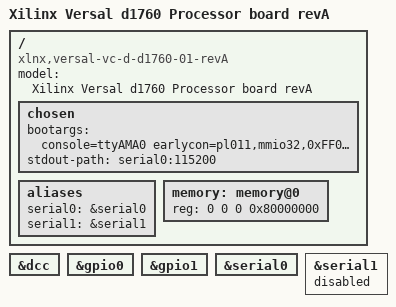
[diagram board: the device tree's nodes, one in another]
// SPDX-License-Identifier: GPL-2.0
/*
 * dts file for Xilinx Versal
 *
 * (C) Copyright 2019, Xilinx, Inc.
 *
 * Michal Simek <michal.simek@xilinx.com>
 */

#include "versal.dtsi"
#include "versal-clk.dtsi"

/ {
	compatible = "xlnx,versal-vc-d-d1760-01-revA",
		     "xlnx,versal-vc-d-d1760-01",
		     "xlnx,versal-vc-d-d1760", "xlnx,versal";
	model = "Xilinx Versal d1760 Processor board revA"; /* xbb2525/v350 */

	chosen {
		bootargs = "console=ttyAMA0 earlycon=pl011,mmio32,0xFF010000,115200n8 clk_ignore_unused";
		stdout-path = "serial0:115200";
	};

	aliases {
		serial0 = &serial0;
		serial1 = &serial1;
	};

	memory: memory@0 {
		device_type = "memory"; /* 16GB total via MC0/1/2/3 */
		reg = <0 0 0 0x80000000>; /* 2GB here */
		/* <0x8 0x0 0x3 0x80000000> */ /* 12GB - enable it later */
	};
};

&dcc {
	status = "okay";
};

&gpio0 {
	status = "okay";
};

&gpio1 {
	status = "okay";
};

&serial0 {
	status = "okay";
};

&serial1 {
	status = "disabled"; /* communication with MSP432 */
};
